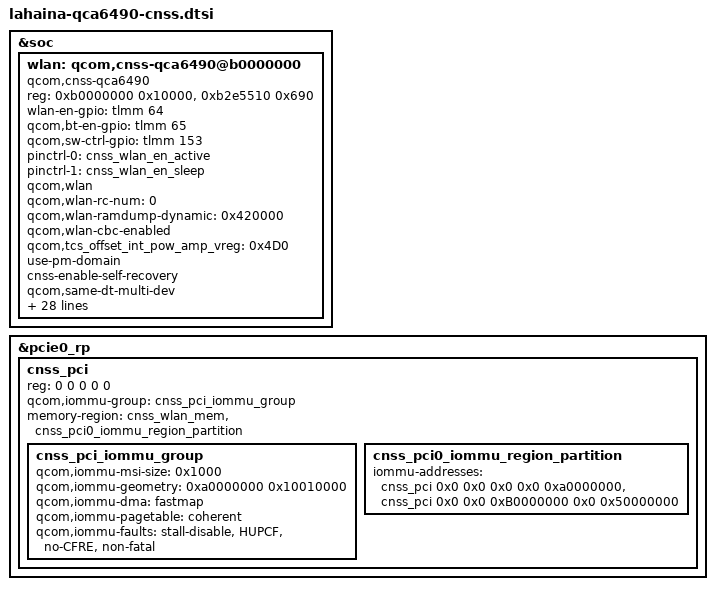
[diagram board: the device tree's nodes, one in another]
// SPDX-License-Identifier: BSD-3-Clause

/*
 * Copyright (c) Qualcomm Technologies, Inc. and/or its subsidiaries.
 */

#include <dt-bindings/interconnect/qcom,lahaina.h>
&soc {
	wlan: qcom,cnss-qca6490@b0000000 {
		compatible = "qcom,cnss-qca6490";
		reg = <0xb0000000 0x10000>,
		      <0xb2e5510 0x690>;
		reg-names = "smmu_iova_ipa", "tcs_cmd";
		wlan-en-gpio = <&tlmm 64 0>;
		qcom,bt-en-gpio = <&tlmm 65 0>;
		qcom,sw-ctrl-gpio = <&tlmm 153 0>;
		pinctrl-names = "wlan_en_active", "wlan_en_sleep";
		pinctrl-0 = <&cnss_wlan_en_active>;
		pinctrl-1 = <&cnss_wlan_en_sleep>;
		qcom,wlan;
		qcom,wlan-rc-num = <0>;
		qcom,wlan-ramdump-dynamic = <0x420000>;
		qcom,wlan-cbc-enabled;
		/* RPMH_PDC_WLAN_RF_TCS<6>_CMD<2> offset */
		qcom,tcs_offset_int_pow_amp_vreg = <0x4D0>;
		use-pm-domain;
		cnss-enable-self-recovery;
		qcom,same-dt-multi-dev;

		vdd-wlan-aon-supply = <&S2E>;
		qcom,vdd-wlan-aon-config = <1012000 1012000 0 0 1>;
		vdd-wlan-dig-supply = <&S11B>;
		qcom,vdd-wlan-dig-config = <1012000 1012000 0 0 1>;
		vdd-wlan-io-supply = <&S10B>;
		qcom,vdd-wlan-io-config = <1800000 1800000 0 0 1>;
		vdd-wlan-rfa1-supply = <&S1C>;
		qcom,vdd-wlan-rfa1-config = <1900000 1952000 0 0 1>;
		vdd-wlan-rfa2-supply = <&S12B>;
		qcom,vdd-wlan-rfa2-config = <1350000 1360000 0 0 1>;
		wlan-ant-switch-supply = <&L7E>;
		qcom,wlan-ant-switch-config = <2800000 2800000 0 0 0>;

		interconnects =
		<&aggre2_noc MASTER_PCIE_0 &aggre2_noc SLAVE_ANOC_PCIE_GEM_NOC>,
		<&gem_noc MASTER_ANOC_PCIE_GEM_NOC &mc_virt SLAVE_EBI1>;
		interconnect-names = "pcie_to_memnoc", "memnoc_to_ddr";

		qcom,icc-path-count = <2>;
		qcom,bus-bw-cfg-count = <7>;
		qcom,bus-bw-cfg =
		/** ICC Path 1 **/
		<0 0>, /* no vote */
		/* idle: 0-18 Mbps snoc/anoc: 100 Mhz ddr: 451.2 MHz */
		<2250 390000>,
		/* low: 18-60 Mbps snoc/anoc: 100 Mhz ddr: 451.2 MHz */
		<7500 390000>,
		/* medium: 60-240 Mbps snoc/anoc: 200 Mhz ddr: 451.2 MHz */
		<30000 790000>,
		/* high: 240-1080 Mbps snoc/anoc: 200 Mhz ddr: 451.2 MHz */
		<100000 790000>,
		/* very high: > 1080 Mbps snoc/anoc: 403 Mhz ddr: 451.2 MHz */
		<175000 1600000>,
		/* low (latency critical): 18-60 Mbps snoc/anoc: 200 Mhz
		 * ddr: 547.2 MHz
		 */
		<7500 390000>,

		/** ICC Path 2 **/
		<0 0>,
		<2250 1804800>,
		<7500 1804800>,
		<30000 1804800>,
		<100000 1804800>,
		<175000 6220800>,
		<7500 2188800>;

	};
};

&pcie0_rp {

	cnss_pci: cnss_pci {
		reg = <0 0 0 0 0>;
		qcom,iommu-group = <&cnss_pci_iommu_group>;
		memory-region = <&cnss_wlan_mem &cnss_pci0_iommu_region_partition>;

		#address-cells = <1>;
		#size-cells = <1>;

		cnss_pci_iommu_group: cnss_pci_iommu_group {
			qcom,iommu-msi-size = <0x1000>;
			qcom,iommu-geometry = <0xa0000000 0x10010000>;
			qcom,iommu-dma = "fastmap";
			qcom,iommu-pagetable = "coherent";
			qcom,iommu-faults = "stall-disable", "HUPCF", "no-CFRE",
					    "non-fatal";
		};

		cnss_pci0_iommu_region_partition: cnss_pci0_iommu_region_partition {
			/**
			 * qcom,iommu-dma-addr-pool = <0xa0000000 0x10000000> conversion:
			 * 0x0 0xA0000000 - first range from above dma-addr pool
			 * 0x0 0xB0000000 = 0xa0000000 + 0x10000000
			 * 0x0 0x50000000 = 100000000 - 0xB0000000
			 */
			 /* address-cells =3 size-cells=2 from yupik-pcie.dtsi */
			iommu-addresses = <&cnss_pci 0x0 0x0 0x0 0x0 0xa0000000>,
					  <&cnss_pci 0x0 0x0 0xB0000000 0x0 0x50000000>;
		};
	};
};
